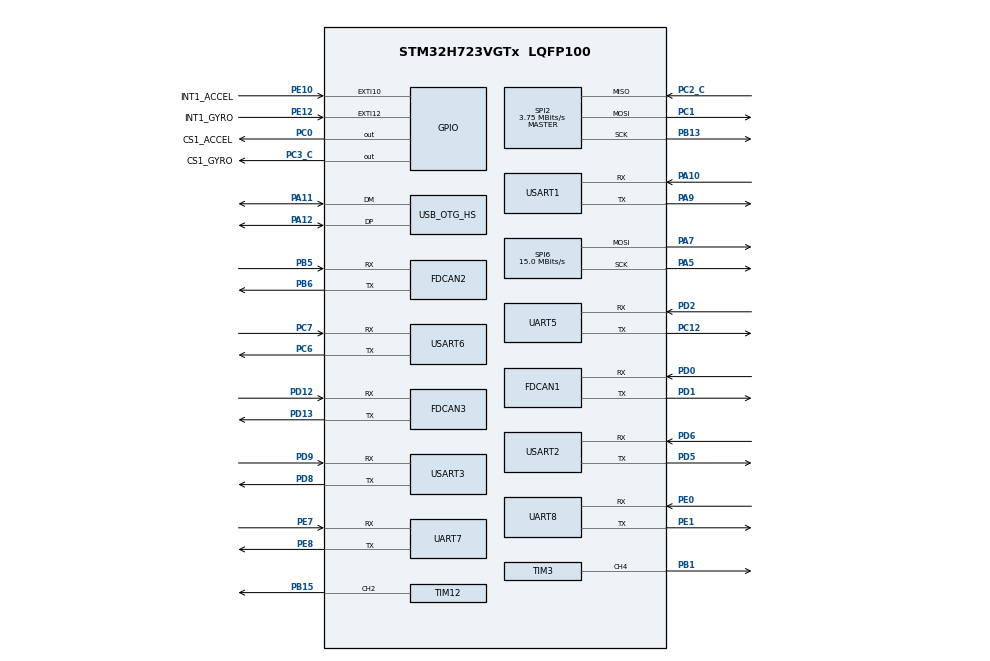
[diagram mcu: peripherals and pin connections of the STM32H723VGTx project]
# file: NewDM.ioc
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Bdma.Request0=SPI6_TX
Bdma.RequestsNb=1
Bdma.SPI6_TX.0.Direction=DMA_MEMORY_TO_PERIPH
Bdma.SPI6_TX.0.EventEnable=DISABLE
Bdma.SPI6_TX.0.Instance=BDMA_Channel0
Bdma.SPI6_TX.0.MemDataAlignment=DMA_MDATAALIGN_BYTE
Bdma.SPI6_TX.0.MemInc=DMA_MINC_ENABLE
Bdma.SPI6_TX.0.Mode=DMA_NORMAL
Bdma.SPI6_TX.0.PeriphDataAlignment=DMA_PDATAALIGN_BYTE
Bdma.SPI6_TX.0.PeriphInc=DMA_PINC_DISABLE
Bdma.SPI6_TX.0.Polarity=HAL_DMAMUX_REQ_GEN_RISING
Bdma.SPI6_TX.0.Priority=DMA_PRIORITY_VERY_HIGH
Bdma.SPI6_TX.0.RequestNumber=1
Bdma.SPI6_TX.0.SignalID=NONE
Bdma.SPI6_TX.0.SyncEnable=DISABLE
Bdma.SPI6_TX.0.SyncPolarity=HAL_DMAMUX_SYNC_NO_EVENT
Bdma.SPI6_TX.0.SyncRequestNumber=1
Bdma.SPI6_TX.0.SyncSignalID=NONE
CORTEX_M7.default_mode_Activation=1
Dma.Request0=USART1_RX
Dma.Request1=USART1_TX
Dma.Request10=UART8_RX
Dma.Request11=UART8_TX
Dma.Request12=SPI2_RX
Dma.Request13=SPI2_TX
Dma.Request14=USART6_RX
Dma.Request15=USART6_TX
Dma.Request2=USART2_RX
Dma.Request3=USART2_TX
Dma.Request4=USART3_RX
Dma.Request5=USART3_TX
Dma.Request6=UART5_RX
Dma.Request7=UART5_TX
Dma.Request8=UART7_RX
Dma.Request9=UART7_TX
Dma.SPI2_RX.12.Direction=DMA_PERIPH_TO_MEMORY
Dma.SPI2_RX.12.EventEnable=DISABLE
Dma.SPI2_RX.12.FIFOMode=DMA_FIFOMODE_DISABLE
Dma.SPI2_RX.12.Instance=DMA2_Stream4
Dma.SPI2_RX.12.MemDataAlignment=DMA_MDATAALIGN_BYTE
Dma.SPI2_RX.12.MemInc=DMA_MINC_ENABLE
Dma.SPI2_RX.12.Mode=DMA_NORMAL
Dma.SPI2_RX.12.PeriphDataAlignment=DMA_PDATAALIGN_BYTE
Dma.SPI2_RX.12.PeriphInc=DMA_PINC_DISABLE
Dma.SPI2_RX.12.Polarity=HAL_DMAMUX_REQ_GEN_RISING
Dma.SPI2_RX.12.Priority=DMA_PRIORITY_VERY_HIGH
Dma.SPI2_RX.12.RequestNumber=1
Dma.SPI2_RX.12.SignalID=NONE
Dma.SPI2_RX.12.SyncEnable=DISABLE
Dma.SPI2_RX.12.SyncPolarity=HAL_DMAMUX_SYNC_NO_EVENT
Dma.SPI2_RX.12.SyncRequestNumber=1
Dma.SPI2_RX.12.SyncSignalID=NONE
Dma.SPI2_TX.13.Direction=DMA_MEMORY_TO_PERIPH
Dma.SPI2_TX.13.EventEnable=DISABLE
Dma.SPI2_TX.13.FIFOMode=DMA_FIFOMODE_DISABLE
Dma.SPI2_TX.13.Instance=DMA2_Stream5
Dma.SPI2_TX.13.MemDataAlignment=DMA_MDATAALIGN_BYTE
Dma.SPI2_TX.13.MemInc=DMA_MINC_ENABLE
Dma.SPI2_TX.13.Mode=DMA_NORMAL
Dma.SPI2_TX.13.PeriphDataAlignment=DMA_PDATAALIGN_BYTE
Dma.SPI2_TX.13.PeriphInc=DMA_PINC_DISABLE
Dma.SPI2_TX.13.Polarity=HAL_DMAMUX_REQ_GEN_RISING
Dma.SPI2_TX.13.Priority=DMA_PRIORITY_MEDIUM
Dma.SPI2_TX.13.RequestNumber=1
Dma.SPI2_TX.13.SignalID=NONE
Dma.SPI2_TX.13.SyncEnable=DISABLE
Dma.SPI2_TX.13.SyncPolarity=HAL_DMAMUX_SYNC_NO_EVENT
Dma.SPI2_TX.13.SyncRequestNumber=1
Dma.SPI2_TX.13.SyncSignalID=NONE
Dma.UART5_RX.6.Direction=DMA_PERIPH_TO_MEMORY
Dma.UART5_RX.6.EventEnable=DISABLE
Dma.UART5_RX.6.FIFOMode=DMA_FIFOMODE_DISABLE
Dma.UART5_RX.6.Instance=DMA1_Stream6
Dma.UART5_RX.6.MemDataAlignment=DMA_MDATAALIGN_BYTE
Dma.UART5_RX.6.MemInc=DMA_MINC_ENABLE
Dma.UART5_RX.6.Mode=DMA_NORMAL
Dma.UART5_RX.6.PeriphDataAlignment=DMA_PDATAALIGN_BYTE
Dma.UART5_RX.6.PeriphInc=DMA_PINC_DISABLE
Dma.UART5_RX.6.Polarity=HAL_DMAMUX_REQ_GEN_RISING
Dma.UART5_RX.6.Priority=DMA_PRIORITY_LOW
Dma.UART5_RX.6.RequestNumber=1
Dma.UART5_RX.6.SignalID=NONE
Dma.UART5_RX.6.SyncEnable=DISABLE
Dma.UART5_RX.6.SyncPolarity=HAL_DMAMUX_SYNC_NO_EVENT
Dma.UART5_RX.6.SyncRequestNumber=1
Dma.UART5_RX.6.SyncSignalID=NONE
Dma.UART5_TX.7.Direction=DMA_MEMORY_TO_PERIPH
Dma.UART5_TX.7.EventEnable=DISABLE
Dma.UART5_TX.7.FIFOMode=DMA_FIFOMODE_DISABLE
Dma.UART5_TX.7.Instance=DMA1_Stream7
Dma.UART5_TX.7.MemDataAlignment=DMA_MDATAALIGN_BYTE
Dma.UART5_TX.7.MemInc=DMA_MINC_ENABLE
Dma.UART5_TX.7.Mode=DMA_NORMAL
Dma.UART5_TX.7.PeriphDataAlignment=DMA_PDATAALIGN_BYTE
Dma.UART5_TX.7.PeriphInc=DMA_PINC_DISABLE
Dma.UART5_TX.7.Polarity=HAL_DMAMUX_REQ_GEN_RISING
Dma.UART5_TX.7.Priority=DMA_PRIORITY_LOW
Dma.UART5_TX.7.RequestNumber=1
Dma.UART5_TX.7.SignalID=NONE
Dma.UART5_TX.7.SyncEnable=DISABLE
Dma.UART5_TX.7.SyncPolarity=HAL_DMAMUX_SYNC_NO_EVENT
Dma.UART5_TX.7.SyncRequestNumber=1
Dma.UART5_TX.7.SyncSignalID=NONE
Dma.UART7_RX.8.Direction=DMA_PERIPH_TO_MEMORY
Dma.UART7_RX.8.EventEnable=DISABLE
Dma.UART7_RX.8.FIFOMode=DMA_FIFOMODE_DISABLE
Dma.UART7_RX.8.Instance=DMA2_Stream0
Dma.UART7_RX.8.MemDataAlignment=DMA_MDATAALIGN_BYTE
Dma.UART7_RX.8.MemInc=DMA_MINC_ENABLE
Dma.UART7_RX.8.Mode=DMA_NORMAL
Dma.UART7_RX.8.PeriphDataAlignment=DMA_PDATAALIGN_BYTE
Dma.UART7_RX.8.PeriphInc=DMA_PINC_DISABLE
Dma.UART7_RX.8.Polarity=HAL_DMAMUX_REQ_GEN_RISING
Dma.UART7_RX.8.Priority=DMA_PRIORITY_LOW
Dma.UART7_RX.8.RequestNumber=1
Dma.UART7_RX.8.SignalID=NONE
Dma.UART7_RX.8.SyncEnable=DISABLE
Dma.UART7_RX.8.SyncPolarity=HAL_DMAMUX_SYNC_NO_EVENT
Dma.UART7_RX.8.SyncRequestNumber=1
Dma.UART7_RX.8.SyncSignalID=NONE
Dma.UART7_TX.9.Direction=DMA_MEMORY_TO_PERIPH
Dma.UART7_TX.9.EventEnable=DISABLE
Dma.UART7_TX.9.FIFOMode=DMA_FIFOMODE_DISABLE
Dma.UART7_TX.9.Instance=DMA2_Stream1
Dma.UART7_TX.9.MemDataAlignment=DMA_MDATAALIGN_BYTE
Dma.UART7_TX.9.MemInc=DMA_MINC_ENABLE
Dma.UART7_TX.9.Mode=DMA_NORMAL
Dma.UART7_TX.9.PeriphDataAlignment=DMA_PDATAALIGN_BYTE
Dma.UART7_TX.9.PeriphInc=DMA_PINC_DISABLE
Dma.UART7_TX.9.Polarity=HAL_DMAMUX_REQ_GEN_RISING
Dma.UART7_TX.9.Priority=DMA_PRIORITY_LOW
Dma.UART7_TX.9.RequestNumber=1
Dma.UART7_TX.9.SignalID=NONE
Dma.UART7_TX.9.SyncEnable=DISABLE
Dma.UART7_TX.9.SyncPolarity=HAL_DMAMUX_SYNC_NO_EVENT
Dma.UART7_TX.9.SyncRequestNumber=1
Dma.UART7_TX.9.SyncSignalID=NONE
Dma.UART8_RX.10.Direction=DMA_PERIPH_TO_MEMORY
Dma.UART8_RX.10.EventEnable=DISABLE
Dma.UART8_RX.10.FIFOMode=DMA_FIFOMODE_DISABLE
Dma.UART8_RX.10.Instance=DMA2_Stream2
Dma.UART8_RX.10.MemDataAlignment=DMA_MDATAALIGN_BYTE
Dma.UART8_RX.10.MemInc=DMA_MINC_ENABLE
Dma.UART8_RX.10.Mode=DMA_NORMAL
Dma.UART8_RX.10.PeriphDataAlignment=DMA_PDATAALIGN_BYTE
Dma.UART8_RX.10.PeriphInc=DMA_PINC_DISABLE
Dma.UART8_RX.10.Polarity=HAL_DMAMUX_REQ_GEN_RISING
Dma.UART8_RX.10.Priority=DMA_PRIORITY_LOW
Dma.UART8_RX.10.RequestNumber=1
Dma.UART8_RX.10.SignalID=NONE
Dma.UART8_RX.10.SyncEnable=DISABLE
Dma.UART8_RX.10.SyncPolarity=HAL_DMAMUX_SYNC_NO_EVENT
Dma.UART8_RX.10.SyncRequestNumber=1
Dma.UART8_RX.10.SyncSignalID=NONE
Dma.UART8_TX.11.Direction=DMA_MEMORY_TO_PERIPH
Dma.UART8_TX.11.EventEnable=DISABLE
Dma.UART8_TX.11.FIFOMode=DMA_FIFOMODE_DISABLE
Dma.UART8_TX.11.Instance=DMA2_Stream3
Dma.UART8_TX.11.MemDataAlignment=DMA_MDATAALIGN_BYTE
Dma.UART8_TX.11.MemInc=DMA_MINC_ENABLE
Dma.UART8_TX.11.Mode=DMA_NORMAL
Dma.UART8_TX.11.PeriphDataAlignment=DMA_PDATAALIGN_BYTE
Dma.UART8_TX.11.PeriphInc=DMA_PINC_DISABLE
Dma.UART8_TX.11.Polarity=HAL_DMAMUX_REQ_GEN_RISING
Dma.UART8_TX.11.Priority=DMA_PRIORITY_LOW
Dma.UART8_TX.11.RequestNumber=1
Dma.UART8_TX.11.SignalID=NONE
Dma.UART8_TX.11.SyncEnable=DISABLE
Dma.UART8_TX.11.SyncPolarity=HAL_DMAMUX_SYNC_NO_EVENT
Dma.UART8_TX.11.SyncRequestNumber=1
Dma.UART8_TX.11.SyncSignalID=NONE
Dma.USART1_RX.0.Direction=DMA_PERIPH_TO_MEMORY
Dma.USART1_RX.0.EventEnable=DISABLE
Dma.USART1_RX.0.FIFOMode=DMA_FIFOMODE_DISABLE
Dma.USART1_RX.0.Instance=DMA1_Stream0
Dma.USART1_RX.0.MemDataAlignment=DMA_MDATAALIGN_BYTE
Dma.USART1_RX.0.MemInc=DMA_MINC_ENABLE
Dma.USART1_RX.0.Mode=DMA_NORMAL
Dma.USART1_RX.0.PeriphDataAlignment=DMA_PDATAALIGN_BYTE
Dma.USART1_RX.0.PeriphInc=DMA_PINC_DISABLE
Dma.USART1_RX.0.Polarity=HAL_DMAMUX_REQ_GEN_RISING
Dma.USART1_RX.0.Priority=DMA_PRIORITY_LOW
Dma.USART1_RX.0.RequestNumber=1
Dma.USART1_RX.0.SignalID=NONE
Dma.USART1_RX.0.SyncEnable=DISABLE
Dma.USART1_RX.0.SyncPolarity=HAL_DMAMUX_SYNC_NO_EVENT
Dma.USART1_RX.0.SyncRequestNumber=1
Dma.USART1_RX.0.SyncSignalID=NONE
Dma.USART1_TX.1.Direction=DMA_MEMORY_TO_PERIPH
Dma.USART1_TX.1.EventEnable=DISABLE
Dma.USART1_TX.1.FIFOMode=DMA_FIFOMODE_DISABLE
Dma.USART1_TX.1.Instance=DMA1_Stream1
Dma.USART1_TX.1.MemDataAlignment=DMA_MDATAALIGN_BYTE
Dma.USART1_TX.1.MemInc=DMA_MINC_ENABLE
Dma.USART1_TX.1.Mode=DMA_NORMAL
Dma.USART1_TX.1.PeriphDataAlignment=DMA_PDATAALIGN_BYTE
Dma.USART1_TX.1.PeriphInc=DMA_PINC_DISABLE
Dma.USART1_TX.1.Polarity=HAL_DMAMUX_REQ_GEN_RISING
Dma.USART1_TX.1.Priority=DMA_PRIORITY_LOW
Dma.USART1_TX.1.RequestNumber=1
Dma.USART1_TX.1.SignalID=NONE
Dma.USART1_TX.1.SyncEnable=DISABLE
Dma.USART1_TX.1.SyncPolarity=HAL_DMAMUX_SYNC_NO_EVENT
Dma.USART1_TX.1.SyncRequestNumber=1
Dma.USART1_TX.1.SyncSignalID=NONE
Dma.USART2_RX.2.Direction=DMA_PERIPH_TO_MEMORY
Dma.USART2_RX.2.EventEnable=DISABLE
Dma.USART2_RX.2.FIFOMode=DMA_FIFOMODE_DISABLE
Dma.USART2_RX.2.Instance=DMA1_Stream2
Dma.USART2_RX.2.MemDataAlignment=DMA_MDATAALIGN_BYTE
Dma.USART2_RX.2.MemInc=DMA_MINC_ENABLE
Dma.USART2_RX.2.Mode=DMA_NORMAL
Dma.USART2_RX.2.PeriphDataAlignment=DMA_PDATAALIGN_BYTE
Dma.USART2_RX.2.PeriphInc=DMA_PINC_DISABLE
Dma.USART2_RX.2.Polarity=HAL_DMAMUX_REQ_GEN_RISING
Dma.USART2_RX.2.Priority=DMA_PRIORITY_LOW
Dma.USART2_RX.2.RequestNumber=1
Dma.USART2_RX.2.SignalID=NONE
Dma.USART2_RX.2.SyncEnable=DISABLE
Dma.USART2_RX.2.SyncPolarity=HAL_DMAMUX_SYNC_NO_EVENT
Dma.USART2_RX.2.SyncRequestNumber=1
Dma.USART2_RX.2.SyncSignalID=NONE
Dma.USART2_TX.3.Direction=DMA_MEMORY_TO_PERIPH
Dma.USART2_TX.3.EventEnable=DISABLE
Dma.USART2_TX.3.FIFOMode=DMA_FIFOMODE_DISABLE
Dma.USART2_TX.3.Instance=DMA1_Stream3
Dma.USART2_TX.3.MemDataAlignment=DMA_MDATAALIGN_BYTE
Dma.USART2_TX.3.MemInc=DMA_MINC_ENABLE
Dma.USART2_TX.3.Mode=DMA_NORMAL
Dma.USART2_TX.3.PeriphDataAlignment=DMA_PDATAALIGN_BYTE
Dma.USART2_TX.3.PeriphInc=DMA_PINC_DISABLE
Dma.USART2_TX.3.Polarity=HAL_DMAMUX_REQ_GEN_RISING
Dma.USART2_TX.3.Priority=DMA_PRIORITY_LOW
Dma.USART2_TX.3.RequestNumber=1
Dma.USART2_TX.3.SignalID=NONE
Dma.USART2_TX.3.SyncEnable=DISABLE
Dma.USART2_TX.3.SyncPolarity=HAL_DMAMUX_SYNC_NO_EVENT
Dma.USART2_TX.3.SyncRequestNumber=1
Dma.USART2_TX.3.SyncSignalID=NONE
Dma.USART3_RX.4.Direction=DMA_PERIPH_TO_MEMORY
Dma.USART3_RX.4.EventEnable=DISABLE
Dma.USART3_RX.4.FIFOMode=DMA_FIFOMODE_DISABLE
Dma.USART3_RX.4.Instance=DMA1_Stream4
Dma.USART3_RX.4.MemDataAlignment=DMA_MDATAALIGN_BYTE
Dma.USART3_RX.4.MemInc=DMA_MINC_ENABLE
Dma.USART3_RX.4.Mode=DMA_NORMAL
Dma.USART3_RX.4.PeriphDataAlignment=DMA_PDATAALIGN_BYTE
Dma.USART3_RX.4.PeriphInc=DMA_PINC_DISABLE
Dma.USART3_RX.4.Polarity=HAL_DMAMUX_REQ_GEN_RISING
Dma.USART3_RX.4.Priority=DMA_PRIORITY_LOW
Dma.USART3_RX.4.RequestNumber=1
Dma.USART3_RX.4.SignalID=NONE
Dma.USART3_RX.4.SyncEnable=DISABLE
Dma.USART3_RX.4.SyncPolarity=HAL_DMAMUX_SYNC_NO_EVENT
Dma.USART3_RX.4.SyncRequestNumber=1
Dma.USART3_RX.4.SyncSignalID=NONE
Dma.USART3_TX.5.Direction=DMA_MEMORY_TO_PERIPH
Dma.USART3_TX.5.EventEnable=DISABLE
Dma.USART3_TX.5.FIFOMode=DMA_FIFOMODE_DISABLE
Dma.USART3_TX.5.Instance=DMA1_Stream5
Dma.USART3_TX.5.MemDataAlignment=DMA_MDATAALIGN_BYTE
Dma.USART3_TX.5.MemInc=DMA_MINC_ENABLE
Dma.USART3_TX.5.Mode=DMA_NORMAL
Dma.USART3_TX.5.PeriphDataAlignment=DMA_PDATAALIGN_BYTE
Dma.USART3_TX.5.PeriphInc=DMA_PINC_DISABLE
Dma.USART3_TX.5.Polarity=HAL_DMAMUX_REQ_GEN_RISING
Dma.USART3_TX.5.Priority=DMA_PRIORITY_LOW
Dma.USART3_TX.5.RequestNumber=1
Dma.USART3_TX.5.SignalID=NONE
Dma.USART3_TX.5.SyncEnable=DISABLE
Dma.USART3_TX.5.SyncPolarity=HAL_DMAMUX_SYNC_NO_EVENT
Dma.USART3_TX.5.SyncRequestNumber=1
Dma.USART3_TX.5.SyncSignalID=NONE
Dma.USART6_RX.14.Direction=DMA_PERIPH_TO_MEMORY
Dma.USART6_RX.14.EventEnable=DISABLE
Dma.USART6_RX.14.FIFOMode=DMA_FIFOMODE_DISABLE
Dma.USART6_RX.14.Instance=DMA2_Stream6
Dma.USART6_RX.14.MemDataAlignment=DMA_MDATAALIGN_BYTE
Dma.USART6_RX.14.MemInc=DMA_MINC_ENABLE
Dma.USART6_RX.14.Mode=DMA_NORMAL
Dma.USART6_RX.14.PeriphDataAlignment=DMA_PDATAALIGN_BYTE
Dma.USART6_RX.14.PeriphInc=DMA_PINC_DISABLE
Dma.USART6_RX.14.Polarity=HAL_DMAMUX_REQ_GEN_RISING
Dma.USART6_RX.14.Priority=DMA_PRIORITY_LOW
Dma.USART6_RX.14.RequestNumber=1
Dma.USART6_RX.14.SignalID=NONE
Dma.USART6_RX.14.SyncEnable=DISABLE
Dma.USART6_RX.14.SyncPolarity=HAL_DMAMUX_SYNC_NO_EVENT
Dma.USART6_RX.14.SyncRequestNumber=1
Dma.USART6_RX.14.SyncSignalID=NONE
Dma.USART6_TX.15.Direction=DMA_MEMORY_TO_PERIPH
Dma.USART6_TX.15.EventEnable=DISABLE
Dma.USART6_TX.15.FIFOMode=DMA_FIFOMODE_DISABLE
Dma.USART6_TX.15.Instance=DMA2_Stream7
Dma.USART6_TX.15.MemDataAlignment=DMA_MDATAALIGN_BYTE
Dma.USART6_TX.15.MemInc=DMA_MINC_ENABLE
Dma.USART6_TX.15.Mode=DMA_NORMAL
Dma.USART6_TX.15.PeriphDataAlignment=DMA_PDATAALIGN_BYTE
Dma.USART6_TX.15.PeriphInc=DMA_PINC_DISABLE
Dma.USART6_TX.15.Polarity=HAL_DMAMUX_REQ_GEN_RISING
Dma.USART6_TX.15.Priority=DMA_PRIORITY_LOW
Dma.USART6_TX.15.RequestNumber=1
Dma.USART6_TX.15.SignalID=NONE
Dma.USART6_TX.15.SyncEnable=DISABLE
Dma.USART6_TX.15.SyncPolarity=HAL_DMAMUX_SYNC_NO_EVENT
Dma.USART6_TX.15.SyncRequestNumber=1
Dma.USART6_TX.15.SyncSignalID=NONE
FDCAN1.CalculateBaudRateNominal=1000000
FDCAN1.CalculateTimeBitNominal=1000
FDCAN1.CalculateTimeQuantumNominal=25.0
FDCAN1.NominalPrescaler=3
FDCAN1.NominalTimeSeg1=29
FDCAN1.NominalTimeSeg2=10
FDCAN1.RxFifo0ElmtsNbr=32
FDCAN1.StdFiltersNbr=1
FDCAN1.TxFifoQueueElmtsNbr=32
FDCAN2.CalculateBaudRateNominal=1000000
FDCAN2.CalculateTimeBitNominal=1000
FDCAN2.CalculateTimeQuantumNominal=25.0
FDCAN2.MessageRAMOffset=0x406
FDCAN2.NominalPrescaler=3
FDCAN2.NominalTimeSeg1=29
FDCAN2.NominalTimeSeg2=10
FDCAN2.RxFifo1ElmtsNbr=32
FDCAN2.StdFiltersNbr=1
FDCAN2.TxFifoQueueElmtsNbr=32
FDCAN3.CalculateBaudRateNominal=1000000
FDCAN3.CalculateTimeBitNominal=1000
FDCAN3.CalculateTimeQuantumNominal=25.0
FDCAN3.MessageRAMOffset=0x812
FDCAN3.NominalPrescaler=3
FDCAN3.NominalTimeSeg1=29
FDCAN3.NominalTimeSeg2=10
FDCAN3.RxFifo1ElmtsNbr=32
FDCAN3.StdFiltersNbr=1
FDCAN3.TxFifoQueueElmtsNbr=32
FREERTOS.Tasks01=defaultTask,24,3192,StartDefaultTask,Default,NULL,Dynamic,NULL,NULL
FREERTOS.configCHECK_FOR_STACK_OVERFLOW=2
FREERTOS.configENABLE_FPU=1
FREERTOS.configGENERATE_RUN_TIME_STATS=1
FREERTOS.configTIMER_TASK_PRIORITY=55
FREERTOS.configTOTAL_HEAP_SIZE=65536
FREERTOS.configUSE_DAEMON_TASK_STARTUP_HOOK=1
FREERTOS.configUSE_MALLOC_FAILED_HOOK=1
FREERTOS.configUSE_STATS_FORMATTING_FUNCTIONS=1
Mcu.Family=STM32H7
Mcu.Name=STM32H723VGTx
Mcu.Package=LQFP100
NVIC.BDMA_Channel0_IRQn=true\:5\:0\:false\:false\:true\:true\:false\:true\:true
NVIC.DMA1_Stream0_IRQn=true\:5\:0\:false\:false\:true\:true\:false\:true\:true
NVIC.DMA1_Stream1_IRQn=true\:5\:0\:false\:false\:true\:true\:false\:true\:true
NVIC.DMA1_Stream2_IRQn=true\:5\:0\:false\:false\:true\:true\:false\:true\:true
NVIC.DMA1_Stream3_IRQn=true\:5\:0\:false\:false\:true\:true\:false\:true\:true
NVIC.DMA1_Stream4_IRQn=true\:5\:0\:false\:false\:true\:true\:false\:true\:true
NVIC.DMA1_Stream5_IRQn=true\:5\:0\:false\:false\:true\:true\:false\:true\:true
NVIC.DMA1_Stream6_IRQn=true\:5\:0\:false\:false\:true\:true\:false\:true\:true
NVIC.DMA1_Stream7_IRQn=true\:5\:0\:false\:false\:true\:true\:false\:true\:true
NVIC.DMA2_Stream0_IRQn=true\:5\:0\:false\:false\:true\:true\:false\:true\:true
NVIC.DMA2_Stream1_IRQn=true\:5\:0\:false\:false\:true\:true\:false\:true\:true
NVIC.DMA2_Stream2_IRQn=true\:5\:0\:false\:false\:true\:true\:false\:true\:true
NVIC.DMA2_Stream3_IRQn=true\:5\:0\:false\:false\:true\:true\:false\:true\:true
NVIC.DMA2_Stream4_IRQn=true\:5\:0\:false\:false\:true\:true\:false\:true\:true
NVIC.DMA2_Stream5_IRQn=true\:5\:0\:false\:false\:true\:true\:false\:true\:true
NVIC.DMA2_Stream6_IRQn=true\:5\:0\:false\:false\:true\:true\:false\:true\:true
NVIC.DMA2_Stream7_IRQn=true\:5\:0\:false\:false\:true\:true\:false\:true\:true
NVIC.EXTI15_10_IRQn=true\:5\:0\:false\:false\:true\:false\:true\:true\:true
NVIC.FDCAN1_IT0_IRQn=true\:5\:0\:true\:false\:true\:true\:true\:true\:true
NVIC.FDCAN1_IT1_IRQn=true\:5\:0\:true\:false\:true\:true\:true\:true\:true
NVIC.FDCAN2_IT0_IRQn=true\:5\:0\:true\:false\:true\:true\:true\:true\:true
NVIC.FDCAN2_IT1_IRQn=true\:5\:0\:true\:false\:true\:true\:true\:true\:true
NVIC.FDCAN3_IT0_IRQn=true\:5\:0\:true\:false\:true\:true\:true\:true\:true
NVIC.FDCAN3_IT1_IRQn=true\:5\:0\:true\:false\:true\:true\:true\:true\:true
NVIC.OTG_HS_IRQn=true\:5\:0\:false\:false\:true\:true\:true\:true\:true
NVIC.PriorityGroup=NVIC_PRIORITYGROUP_4
NVIC.SPI2_IRQn=true\:5\:0\:false\:false\:true\:true\:false\:true\:true
NVIC.SPI6_IRQn=true\:5\:0\:false\:false\:true\:true\:false\:true\:true
NVIC.TIM1_UP_IRQn=true\:15\:0\:false\:false\:true\:false\:false\:true\:true
NVIC.TimeBase=TIM1_UP_IRQn
NVIC.TimeBaseIP=TIM1
NVIC.UART5_IRQn=true\:5\:0\:false\:false\:true\:true\:false\:true\:true
NVIC.UART7_IRQn=true\:5\:0\:false\:false\:true\:true\:true\:true\:true
NVIC.UART8_IRQn=true\:5\:0\:false\:false\:true\:true\:true\:true\:true
NVIC.USART1_IRQn=true\:5\:0\:false\:false\:true\:true\:true\:true\:true
NVIC.USART2_IRQn=true\:5\:0\:false\:false\:true\:true\:true\:true\:true
NVIC.USART3_IRQn=true\:5\:0\:false\:false\:true\:true\:true\:true\:true
NVIC.USART6_IRQn=true\:5\:0\:false\:false\:true\:true\:true\:true\:true
PA10.GPIO_PuPd=GPIO_PULLUP
PA10.Mode=Asynchronous
PA10.Signal=USART1_RX
PA11.Mode=Device_Only_FS
PA11.Signal=USB_OTG_HS_DM
PA12.Mode=Device_Only_FS
PA12.Signal=USB_OTG_HS_DP
PA5.Mode=TX_Only_Simplex_Unidirect_Master
PA5.Signal=SPI6_SCK
PA7.Mode=TX_Only_Simplex_Unidirect_Master
PA7.Signal=SPI6_MOSI
PA9.Mode=Asynchronous
PA9.Signal=USART1_TX
PB1.GPIO_PuPd=GPIO_PULLDOWN
PB1.Signal=S_TIM3_CH4
PB13.Mode=Full_Duplex_Master
PB13.Signal=SPI2_SCK
PB15.Signal=S_TIM12_CH2
PB5.Mode=FDCAN_Activate
PB5.Signal=FDCAN2_RX
PB6.Mode=FDCAN_Activate
PB6.Signal=FDCAN2_TX
PC0.GPIO_Label=CS1_ACCEL
PC0.GPIO_Speed=GPIO_SPEED_FREQ_VERY_HIGH
PC0.PinState=GPIO_PIN_SET
PC0.Signal=GPIO_Output
PC1.Mode=Full_Duplex_Master
PC1.Signal=SPI2_MOSI
PC12.Mode=Asynchronous
PC12.Signal=UART5_TX
PC2_C.GPIO_PuPd=GPIO_PULLUP
PC2_C.Mode=Full_Duplex_Master
PC2_C.Signal=SPI2_MISO
PC3_C.GPIO_Label=CS1_GYRO
PC3_C.GPIO_Speed=GPIO_SPEED_FREQ_VERY_HIGH
PC3_C.PinState=GPIO_PIN_SET
PC3_C.Signal=GPIO_Output
PC6.Mode=Asynchronous
PC6.Signal=USART6_TX
PC7.GPIO_PuPd=GPIO_PULLUP
PC7.Mode=Asynchronous
PC7.Signal=USART6_RX
PD0.Mode=FDCAN_Activate
PD0.Signal=FDCAN1_RX
PD1.Mode=FDCAN_Activate
PD1.Signal=FDCAN1_TX
PD12.Mode=FDCAN_Activate
PD12.Signal=FDCAN3_RX
PD13.Mode=FDCAN_Activate
PD13.Signal=FDCAN3_TX
PD2.GPIO_PuPd=GPIO_PULLUP
PD2.Mode=Asynchronous
PD2.Signal=UART5_RX
PD5.Mode=Asynchronous
PD5.Signal=USART2_TX
PD6.GPIO_PuPd=GPIO_PULLUP
PD6.Mode=Asynchronous
PD6.Signal=USART2_RX
PD8.Mode=Asynchronous
PD8.Signal=USART3_TX
PD9.GPIO_PuPd=GPIO_PULLUP
PD9.Mode=Asynchronous
PD9.Signal=USART3_RX
PE0.GPIO_PuPd=GPIO_PULLUP
PE0.Mode=Asynchronous
PE0.Signal=UART8_RX
PE1.GPIO_PuPd=GPIO_NOPULL
PE1.Mode=Asynchronous
PE1.Signal=UART8_TX
PE10.GPIO_Label=INT1_ACCEL
PE10.GPIO_ModeDefaultEXTI=GPIO_MODE_IT_RISING
PE10.GPIO_PuPd=GPIO_PULLUP
PE10.Signal=GPXTI10
PE12.GPIO_Label=INT1_GYRO
PE12.GPIO_PuPd=GPIO_PULLUP
PE12.Signal=GPXTI12
PE7.GPIO_PuPd=GPIO_PULLUP
PE7.Mode=Asynchronous
PE7.Signal=UART7_RX
PE8.GPIO_PuPd=GPIO_NOPULL
PE8.Mode=Asynchronous
PE8.Signal=UART7_TX
PH0-OSC_IN.Mode=HSE-External-Oscillator
PH0-OSC_IN.Signal=RCC_OSC_IN
PH1-OSC_OUT.Mode=HSE-External-Oscillator
PH1-OSC_OUT.Signal=RCC_OSC_OUT
ProjectManager.HeapSize=0x200
ProjectManager.StackSize=0x400
ProjectManager.TargetToolchain=CMake
RCC.ADCFreq_Value=96000000
RCC.APB1Freq_Value=120000000
RCC.APB2Freq_Value=120000000
RCC.APB3Freq_Value=120000000
RCC.APB4Freq_Value=120000000
RCC.CortexFreq_Value=480000000
RCC.D1PPRE=RCC_APB3_DIV2
RCC.D2PPRE1=RCC_APB1_DIV2
RCC.D2PPRE2=RCC_APB2_DIV2
RCC.D3PPRE=RCC_APB4_DIV2
RCC.DIVM1=2
RCC.DIVM2=2
RCC.DIVN1=40
RCC.DIVN2=16
RCC.DIVP1=1
RCC.DIVQ1=4
RCC.HCLKFreq_Value=240000000
RCC.HPRE=RCC_HCLK_DIV2
RCC.HSE_VALUE=24000000
RCC.PLL3FRACN=0
RCC.PLLFRACN=0
RCC.PLLSourceVirtual=RCC_PLLSOURCE_HSE
RCC.SYSCLKFreq_VALUE=480000000
RCC.SYSCLKSource=RCC_SYSCLKSOURCE_PLLCLK
RCC.USBCLockSelection=RCC_USBCLKSOURCE_HSI48
RCC.USBFreq_Value=48000000
SH.S_TIM12_CH2.0=TIM12_CH2,PWM Generation2 CH2
SH.S_TIM3_CH4.0=TIM3_CH4,PWM Generation4 CH4
SPI2.BaudRatePrescaler=SPI_BAUDRATEPRESCALER_32
SPI2.CalculateBaudRate=3.75 MBits/s
SPI2.DataSize=SPI_DATASIZE_8BIT
SPI2.Direction=SPI_DIRECTION_2LINES
SPI2.Mode=SPI_MODE_MASTER
SPI2.VirtualType=VM_MASTER
SPI6.BaudRatePrescaler=SPI_BAUDRATEPRESCALER_8
SPI6.CLKPhase=SPI_PHASE_1EDGE
SPI6.CalculateBaudRate=15.0 MBits/s
SPI6.DataSize=SPI_DATASIZE_8BIT
SPI6.Direction=SPI_DIRECTION_2LINES_TXONLY
SPI6.Mode=SPI_MODE_MASTER
SPI6.VirtualType=VM_MASTER
TIM12.Channel-PWM\ Generation2\ CH2=TIM_CHANNEL_2
TIM12.Period=1000-1
TIM12.Prescaler=1000-1
TIM3.Channel-PWM\ Generation4\ CH4=TIM_CHANNEL_4
TIM3.Period=1000-1
TIM3.Prescaler=1000-1
USART1.VirtualMode-Asynchronous=VM_ASYNC
USART2.VirtualMode-Asynchronous=VM_ASYNC
USART3.VirtualMode-Asynchronous=VM_ASYNC
USART6.VirtualMode=VM_ASYNC
USB_DEVICE.CLASS_NAME_HS=CDC
USB_DEVICE.VirtualMode=Cdc
USB_DEVICE.VirtualModeHS=Cdc_HS
USB_OTG_HS.VirtualMode-Device_Only_FS=Device_Only_FS
VP_FREERTOS_VS_CMSIS_V2.Mode=CMSIS_V2
VP_MEMORYMAP_VS_MEMORYMAP.Mode=CurAppReg
VP_SYS_VS_tim1.Mode=TIM1
VP_TIM12_VS_ClockSourceINT.Mode=Internal
VP_USB_DEVICE_VS_USB_DEVICE_CDC_HS.Mode=CDC_HS
board=custom

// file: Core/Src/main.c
/* USER CODE BEGIN Header */
/**
  ******************************************************************************
  * @file           : main.c
  * @brief          : Main program body
  ******************************************************************************
  * @attention
  *
  * Copyright (c) 2026 STMicroelectronics.
  * All rights reserved.
  *
  * This software is licensed under terms that can be found in the LICENSE file
  * in the root directory of this software component.
  * If no LICENSE file comes with this software, it is provided AS-IS.
  *
  ******************************************************************************
  */
/* USER CODE END Header */
#include "main.h"
#include "FreeRTOS.h"
#include "cmsis_os2.h"
#include "bdma.h"
#include "dma.h"
#include "fdcan.h"
#include "spi.h"
#include "tim.h"
#include "usart.h"
#include "usb_device.h"
#include "gpio.h"

void SystemClock_Config(void);
static void MPU_Config(void);
void MX_FREERTOS_Init(void);

int main(void)
{

  /* MPU Configuration--------------------------------------------------------*/
  MPU_Config();

  /* MCU Configuration--------------------------------------------------------*/

  /* Reset of all peripherals, Initializes the Flash interface and the Systick. */
  HAL_Init();

  /* USER CODE BEGIN Init */
   HAL_Delay(150);        // 给电源/晶振一点缓过来的时间
  /* USER CODE END Init */

  /* Configure the system clock */
  SystemClock_Config();

  /* Initialize all configured peripherals */
  MX_GPIO_Init();
  MX_DMA_Init();
  MX_BDMA_Init();
  MX_FDCAN1_Init();
  MX_FDCAN2_Init();
  MX_FDCAN3_Init();
  MX_USART1_UART_Init();
  MX_USART2_UART_Init();
  MX_USART3_UART_Init();
  MX_UART5_Init();
  MX_USART6_UART_Init();
  MX_UART7_Init();
  MX_UART8_Init();
  MX_SPI2_Init();
  MX_SPI6_Init();
  MX_TIM12_Init();
  MX_TIM3_Init();
  /* USER CODE BEGIN 2 */

  /* LibXR runs module callbacks (BMI088 data-ready, ...) from the GPIO EXTI
   * handlers, and those callbacks use FreeRTOS ...FromISR() APIs.  Such an
   * interrupt must therefore have a priority numerically >=
   * configLIBRARY_MAX_SYSCALL_INTERRUPT_PRIORITY (5).  CubeMX defaults EXTI
   * priority to 0, which trips vPortValidateInterruptPriority()'s
   * configASSERT() (taskDISABLE_INTERRUPTS(); for(;;)) on the first edge and
   * freezes the whole system.  Keep this override: it is regeneration safe. */
  HAL_NVIC_SetPriority(EXTI15_10_IRQn, 5, 0);

  /* Give the passive buzzer on PB15 (TIM12_CH2) one short beep. */
  __HAL_TIM_SET_COMPARE(&htim12, TIM_CHANNEL_2, htim12.Init.Period / 2U);
  HAL_TIM_PWM_Start(&htim12, TIM_CHANNEL_2);
  HAL_Delay(100);
  HAL_TIM_PWM_Stop(&htim12, TIM_CHANNEL_2);
  __HAL_TIM_SET_COMPARE(&htim12, TIM_CHANNEL_2, 0U);

  /* USER CODE END 2 */

  /* Init scheduler */
  osKernelInitialize();  /* Call init function for freertos objects (in cmsis_os2.c) */
  MX_FREERTOS_Init();

  /* Start scheduler */
  osKernelStart();

  /* We should never get here as control is now taken by the scheduler */

  /* Infinite loop */
  while (1)
  {

  }
}

void SystemClock_Config(void)
{
  RCC_OscInitTypeDef RCC_OscInitStruct = {0};
  RCC_ClkInitTypeDef RCC_ClkInitStruct = {0};

  /** Supply configuration update enable
  */
  HAL_PWREx_ConfigSupply(PWR_LDO_SUPPLY);

  /** Configure the main internal regulator output voltage
  */
  __HAL_PWR_VOLTAGESCALING_CONFIG(PWR_REGULATOR_VOLTAGE_SCALE0);

  while(!__HAL_PWR_GET_FLAG(PWR_FLAG_VOSRDY)) {}

  /** Initializes the RCC Oscillators according to the specified parameters
  * in the RCC_OscInitTypeDef structure.
  */
  RCC_OscInitStruct.OscillatorType = RCC_OSCILLATORTYPE_HSI48|RCC_OSCILLATORTYPE_HSE;
  RCC_OscInitStruct.HSEState = RCC_HSE_ON;
  RCC_OscInitStruct.HSI48State = RCC_HSI48_ON;
  RCC_OscInitStruct.PLL.PLLState = RCC_PLL_ON;
  RCC_OscInitStruct.PLL.PLLSource = RCC_PLLSOURCE_HSE;
  RCC_OscInitStruct.PLL.PLLM = 2;
  RCC_OscInitStruct.PLL.PLLN = 40;
  RCC_OscInitStruct.PLL.PLLP = 1;
  RCC_OscInitStruct.PLL.PLLQ = 4;
  RCC_OscInitStruct.PLL.PLLR = 2;
  RCC_OscInitStruct.PLL.PLLRGE = RCC_PLL1VCIRANGE_3;
  RCC_OscInitStruct.PLL.PLLVCOSEL = RCC_PLL1VCOWIDE;
  RCC_OscInitStruct.PLL.PLLFRACN = 0;
  if (HAL_RCC_OscConfig(&RCC_OscInitStruct) != HAL_OK)
  {
    Error_Handler();
  }

  /** Initializes the CPU, AHB and APB buses clocks
  */
  RCC_ClkInitStruct.ClockType = RCC_CLOCKTYPE_HCLK|RCC_CLOCKTYPE_SYSCLK
                              |RCC_CLOCKTYPE_PCLK1|RCC_CLOCKTYPE_PCLK2
                              |RCC_CLOCKTYPE_D3PCLK1|RCC_CLOCKTYPE_D1PCLK1;
  RCC_ClkInitStruct.SYSCLKSource = RCC_SYSCLKSOURCE_PLLCLK;
  RCC_ClkInitStruct.SYSCLKDivider = RCC_SYSCLK_DIV1;
  RCC_ClkInitStruct.AHBCLKDivider = RCC_HCLK_DIV2;
  RCC_ClkInitStruct.APB3CLKDivider = RCC_APB3_DIV2;
  RCC_ClkInitStruct.APB1CLKDivider = RCC_APB1_DIV2;
  RCC_ClkInitStruct.APB2CLKDivider = RCC_APB2_DIV2;
  RCC_ClkInitStruct.APB4CLKDivider = RCC_APB4_DIV2;

  if (HAL_RCC_ClockConfig(&RCC_ClkInitStruct, FLASH_LATENCY_3) != HAL_OK)
  {
    Error_Handler();
  }
}

 /* MPU Configuration */

void MPU_Config(void)
{
  MPU_Region_InitTypeDef MPU_InitStruct = {0};

  /* Disables the MPU */
  HAL_MPU_Disable();

  /** Initializes and configures the Region and the memory to be protected
  */
  MPU_InitStruct.Enable = MPU_REGION_ENABLE;
  MPU_InitStruct.Number = MPU_REGION_NUMBER0;
  MPU_InitStruct.BaseAddress = 0x0;
  MPU_InitStruct.Size = MPU_REGION_SIZE_4GB;
  MPU_InitStruct.SubRegionDisable = 0x87;
  MPU_InitStruct.TypeExtField = MPU_TEX_LEVEL0;
  MPU_InitStruct.AccessPermission = MPU_REGION_NO_ACCESS;
  MPU_InitStruct.DisableExec = MPU_INSTRUCTION_ACCESS_DISABLE;
  MPU_InitStruct.IsShareable = MPU_ACCESS_SHAREABLE;
  MPU_InitStruct.IsCacheable = MPU_ACCESS_NOT_CACHEABLE;
  MPU_InitStruct.IsBufferable = MPU_ACCESS_NOT_BUFFERABLE;

  HAL_MPU_ConfigRegion(&MPU_InitStruct);
  /* Enables the MPU */
  HAL_MPU_Enable(MPU_PRIVILEGED_DEFAULT);

}

void HAL_TIM_PeriodElapsedCallback(TIM_HandleTypeDef *htim)
{
  if (htim->Instance == TIM1)
  {
    HAL_IncTick();
  }
}

void Error_Handler(void)
{
  __disable_irq();
  while (1)
  {
  }
}

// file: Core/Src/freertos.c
/* USER CODE BEGIN Header */
/**
  ******************************************************************************
  * File Name          : freertos.c
  * Description        : Code for freertos applications
  ******************************************************************************
  * @attention
  *
  * Copyright (c) 2026 STMicroelectronics.
  * All rights reserved.
  *
  * This software is licensed under terms that can be found in the LICENSE file
  * in the root directory of this software component.
  * If no LICENSE file comes with this software, it is provided AS-IS.
  *
  ******************************************************************************
  */
/* USER CODE END Header */

#include "FreeRTOS.h"
#include "task.h"
#include "main.h"
#include "FreeRTOS.h"
#include "cmsis_os2.h"

/* USER CODE BEGIN Includes */
#include "app_main.h"
#include <stdbool.h>

/* USER CODE END Includes */

/* Definitions for defaultTask */
osThreadId_t defaultTaskHandle;
const osThreadAttr_t defaultTask_attributes = {
  .name = "defaultTask",
  .stack_size = 3192 * 4,
  .priority = (osPriority_t) osPriorityNormal,
};

void StartDefaultTask(void *argument);

extern void MX_USB_DEVICE_Init(void);
void MX_FREERTOS_Init(void); /* (MISRA C 2004 rule 8.1) */

/* Hook prototypes */
void configureTimerForRunTimeStats(void);
unsigned long getRunTimeCounterValue(void);
void vApplicationStackOverflowHook(xTaskHandle xTask, char *pcTaskName);
void vApplicationMallocFailedHook(void);
void vApplicationDaemonTaskStartupHook(void);

/* USER CODE BEGIN 1 */
/* Functions needed when configGENERATE_RUN_TIME_STATS is on */
__weak void configureTimerForRunTimeStats(void)
{

}

__weak unsigned long getRunTimeCounterValue(void)
{
return 0;
}
/* USER CODE END 1 */

/* USER CODE BEGIN 4 */
/* Name of the task that overflowed its stack; readable from a debugger once
 * the CPU is stopped in the loop below.  Never print from this hook: it runs
 * inside the PendSV (context switch) exception, so any blocking LibXR call
 * (STDIO mutex, queue, ...) triggers a FreeRTOS configASSERT and turns the
 * overflow into a silent, uninterruptible deadlock. */
volatile const char *g_stack_overflow_task = 0;

void vApplicationStackOverflowHook(xTaskHandle xTask, char *pcTaskName)
{
   /* Run time stack overflow checking is performed if
   configCHECK_FOR_STACK_OVERFLOW is defined to 1 or 2. This hook function is
   called if a stack overflow is detected. */
   (void)xTask;
   g_stack_overflow_task = pcTaskName;
   taskDISABLE_INTERRUPTS();
   for (;;) { }
}
/* USER CODE END 4 */

/* USER CODE BEGIN 5 */
void vApplicationMallocFailedHook(void)
{
   /* vApplicationMallocFailedHook() will only be called if
   configUSE_MALLOC_FAILED_HOOK is set to 1 in FreeRTOSConfig.h. It is a hook
   function that will get called if a call to pvPortMalloc() fails.
   pvPortMalloc() is called internally by the kernel whenever a task, queue,
   timer or semaphore is created. It is also called by various parts of the
   demo application. If heap_1.c or heap_2.c are used, then the size of the
   heap available to pvPortMalloc() is defined by configTOTAL_HEAP_SIZE in
   FreeRTOSConfig.h, and the xPortGetFreeHeapSize() API function can be used
   to query the size of free heap space that remains (although it does not
   provide information on how the remaining heap might be fragmented). */
}
/* USER CODE END 5 */

/* USER CODE BEGIN DAEMON_TASK_STARTUP_HOOK */
void vApplicationDaemonTaskStartupHook(void)
{
}
/* USER CODE END DAEMON_TASK_STARTUP_HOOK */

void MX_FREERTOS_Init(void) {

  /* Create the thread(s) */
  /* creation of defaultTask */
  defaultTaskHandle = osThreadNew(StartDefaultTask, NULL, &defaultTask_attributes);

}

void StartDefaultTask(void *argument)
{
  /* init code for USB_DEVICE */
  MX_USB_DEVICE_Init();
  /* USER CODE BEGIN StartDefaultTask */
  app_main();
  /* Infinite loop */
  for(;;)
  {
    osDelay(1);
  }
  /* USER CODE END StartDefaultTask */
}
